# M4K4A register map
File version: 0.1
Registers are 32-bit, read-write, reset 0x0 unless marked. A register's access mark holds for its fields unless they carry their own. Offsets are from the block's base; [hi:lo] are bit positions; {n}, {i} and the like mark numbered series.

## PJ
Base 0x400C0800
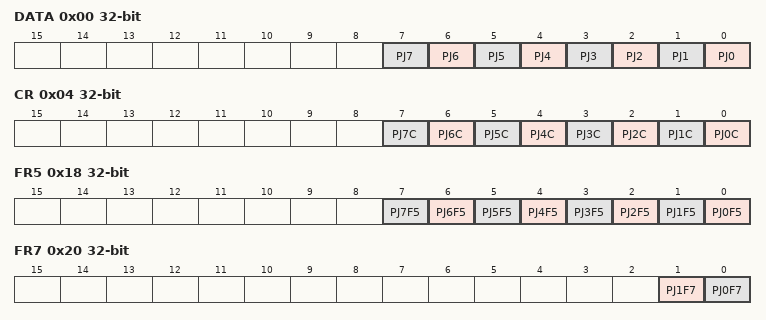
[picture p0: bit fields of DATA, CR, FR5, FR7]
0x00 DATA — PJ Data Register
  [n] PJ{n} (n=0..7)
0x04 CR — PJ Control Register
  [n] PJ{n}C (n=0..7)
0x18 FR5 — PJ Function Register 5
  [n] PJ{n}F5 (n=0..7)
0x1C FR6 — PJ Function Register 6
  [0] PJ0F6
0x20 FR7 — PJ Function Register 7
  [1] PJ1F7, [0] PJ0F7
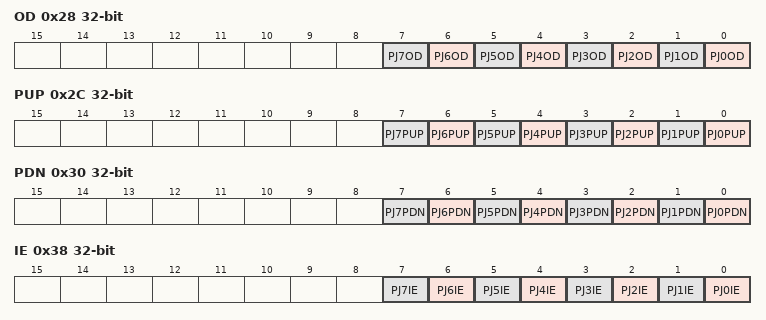
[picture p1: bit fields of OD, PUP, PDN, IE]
0x28 OD — PJ Open Drain Control Register
  [n] PJ{n}OD (n=0..7)
0x2C PUP — PJ Pull-up Control Register
  [n] PJ{n}PUP (n=0..7)
0x30 PDN — PJ Pull-Down Control Register
  [n] PJ{n}PDN (n=0..7)
0x38 IE — PJ Input Enable Control Register
  [n] PJ{n}IE (n=0..7)

## PK
Base 0x400C0900
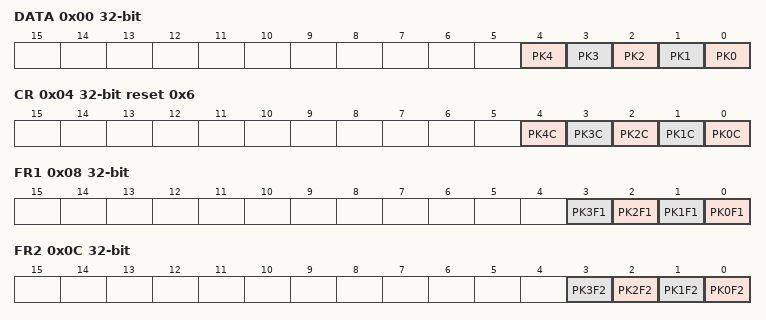
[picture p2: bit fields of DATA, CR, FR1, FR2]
0x00 DATA — PK Data Register
  [n] PK{n} (n=0..4)
0x04 CR reset 0x6 — PK Control Register
  [n] PK{n}C (n=0..4)
0x08 FR1 — PK Function Register 1
  [n] PK{n}F1 (n=0..3)
0x0C FR2 — PK Function Register 2
  [n] PK{n}F2 (n=0..3)
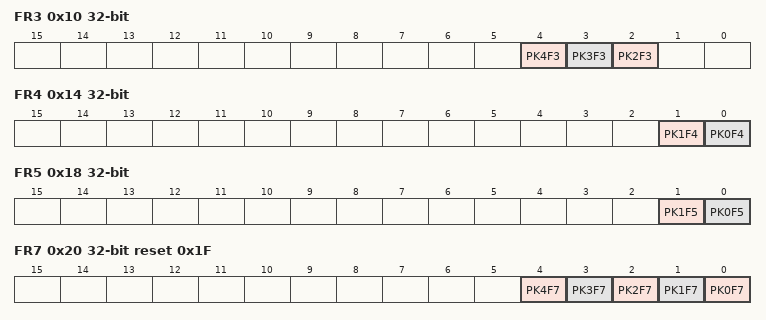
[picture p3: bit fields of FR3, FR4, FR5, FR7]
0x10 FR3 — PK Function Register 3
  [4] PK4F3, [3] PK3F3, [2] PK2F3
0x14 FR4 — PK Function Register 4
  [1] PK1F4, [0] PK0F4
0x18 FR5 — PK Function Register 5
  [1] PK1F5, [0] PK0F5
0x1C FR6 — PK Function Register 6
  [4] PK4F6
0x20 FR7 reset 0x1F — PK Function Register 7
  [n] PK{n}F7 (n=0..4)
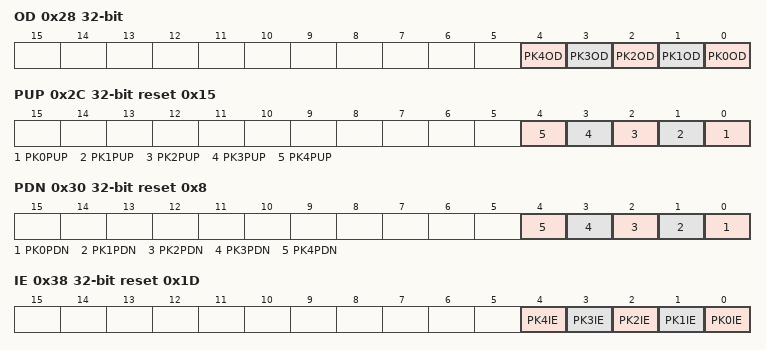
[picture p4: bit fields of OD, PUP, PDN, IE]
0x28 OD — PK Open Drain Control Register
  [n] PK{n}OD (n=0..4)
0x2C PUP reset 0x15 — PK Pull-up Control Register
  [n] PK{n}PUP (n=0..4)
0x30 PDN reset 0x8 — PK Pull-Down Control Register
  [n] PK{n}PDN (n=0..4)
0x38 IE reset 0x1D — PK Input Enable Control Register
  [n] PK{n}IE (n=0..4)

## PL
Base 0x400C0A00
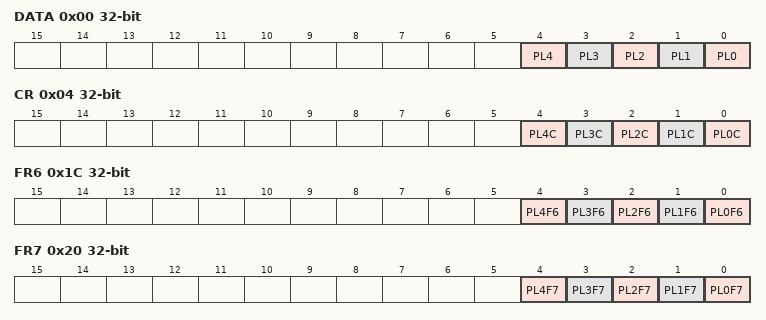
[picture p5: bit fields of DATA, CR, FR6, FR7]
0x00 DATA — PL Data Register
  [n] PL{n} (n=0..4)
0x04 CR — PL Control Register
  [n] PL{n}C (n=0..4)
0x1C FR6 — PL Function Register 6
  [n] PL{n}F6 (n=0..4)
0x20 FR7 — PL Function Register 7
  [n] PL{n}F7 (n=0..4)
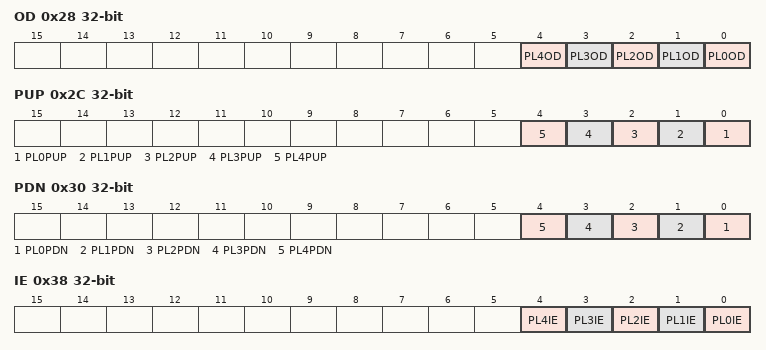
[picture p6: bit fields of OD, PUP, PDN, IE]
0x28 OD — PL Open Drain Control Register
  [n] PL{n}OD (n=0..4)
0x2C PUP — PL Pull-up Control Register
  [n] PL{n}PUP (n=0..4)
0x30 PDN — PL Pull-Down Control Register
  [n] PL{n}PDN (n=0..4)
0x38 IE — PL Input Enable Control Register
  [n] PL{n}IE (n=0..4)

## OFD
Base 0x400F1000
0x00 CR1 reset 0x6 — OFD Control Register 1
  [7:0] OFDWEN
0x04 CR2 — OFD Control Register 2
  [7:0] OFDEN
0x08 MN0 — OFD Lower Detection Frequency Setting Register0
  [11:0] OFDMN0
0x0C MN1 — OFD Lower Detection Frequency Setting Register1
  [11:0] OFDMN1
0x10 MX0 — OFD Higher Detection Frequency Setting Register0
  [11:0] OFDMX0
0x14 MX1 — OFD Higher Detection Frequency Setting Register1
  [11:0] OFDMX1
0x18 RST reset 0x1 — OFD Reset Enable Control Register
  [0] OFDRSTEN
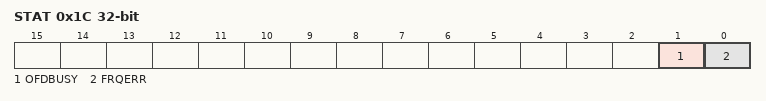
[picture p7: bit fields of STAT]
0x1C STAT ro — OFD Status Register
  [1] OFDBUSY, [0] FRQERR
0x20 MON reset 0x1 — OFD detection target clock 1 monitor setting register
  [0] OFDMON

## CG
Base 0x400F3000
0x00 PROTECT reset 0xC1 — CG Protect Register
  [7:0] PROTECT
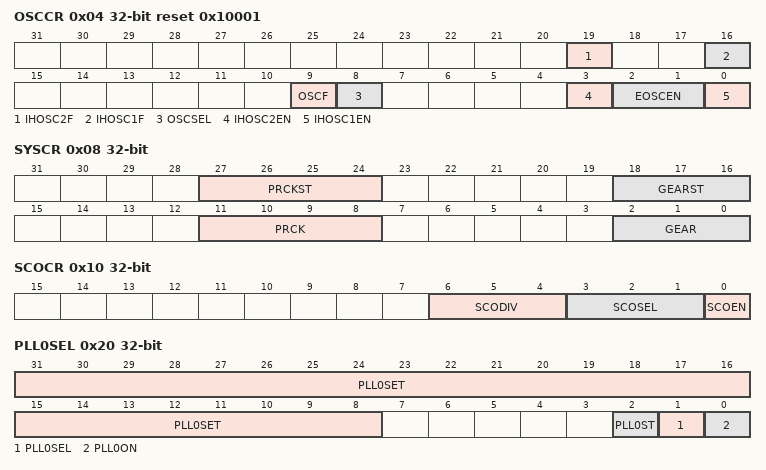
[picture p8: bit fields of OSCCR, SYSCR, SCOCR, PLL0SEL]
0x04 OSCCR reset 0x10001 — CG Oscillation Control Register
  [19] IHOSC2F ro, [16] IHOSC1F ro, [9] OSCF ro, [8] OSCSEL, [3] IHOSC2EN, [2:1] EOSCEN, [0] IHOSC1EN
0x08 SYSCR — CG System clock control register
  [27:24] PRCKST ro, [18:16] GEARST ro, [11:8] PRCK, [2:0] GEAR
0x0C STBYCR — CG Standby Control Register
  [1:0] STBY
0x10 SCOCR — CG SCOUT Control Register
  [6:4] SCODIV, [3:1] SCOSEL, [0] SCOEN
0x20 PLL0SEL — CG PLL select register for fsys
  [31:8] PLL0SET, [2] PLL0ST ro, [1] PLL0SEL, [0] PLL0ON
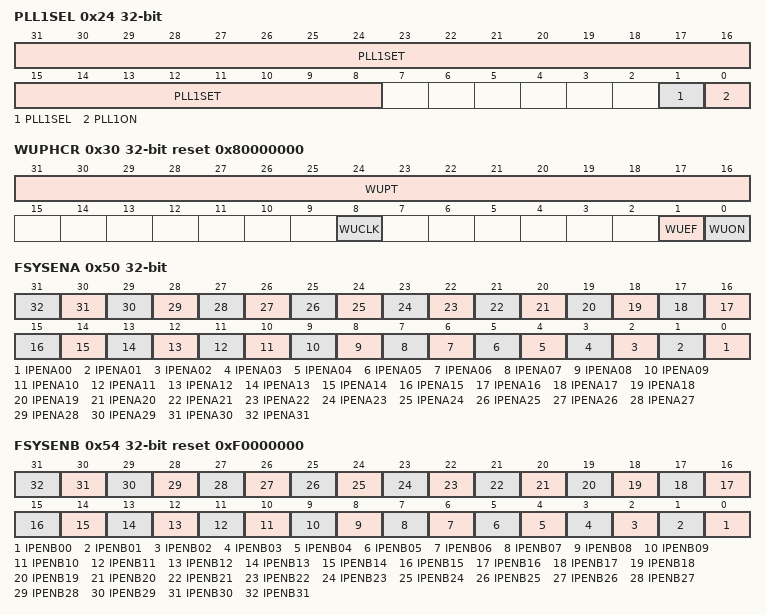
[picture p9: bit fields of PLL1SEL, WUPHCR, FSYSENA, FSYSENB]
0x24 PLL1SEL — CG PLL select register for ADCLK
  [31:8] PLL1SET, [1] PLL1SEL, [0] PLL1ON
0x30 WUPHCR reset 0x80000000 — CG Warmup register for HOSC
  [31:16] WUPT, [8] WUCLK, [1] WUEF ro, [0] WUON wo
0x50 FSYSENA — CG output control register A for fsys clock
  [n] IPENA{n:02} (n=0..31)
0x54 FSYSENB reset 0xF0000000 — CG output control register B for fsys clock
  [n] IPENB{n:02} (n=0..31)
0x58 FCEN — CG output control register for fc clock
  [7] DNFCKEN
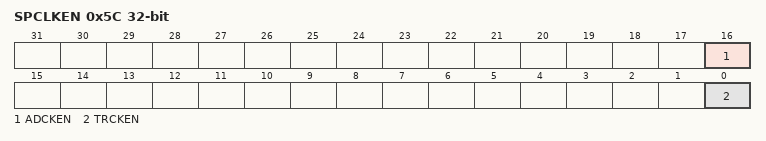
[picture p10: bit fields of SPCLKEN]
0x5C SPCLKEN — CG Output control register for ADC AND TRACE CLOCK
  [16] ADCKEN, [0] TRCKEN
